# CC13x0 register map
File version: 2.0
CPU: CM3 r2p1, little endian, no MPU, no FPU, 0x3 interrupt priority bits, 0x0 interrupts
Registers are 32-bit, read-write, reset 0x0 unless marked. A register's access mark holds for its fields unless they carry their own. Offsets are from the block's base; [hi:lo] are bit positions; {n}, {i} and the like mark numbered series; 'fields as' and 'values as' point back to an identical list.

## AUX_SCE — AUX Sensor Control Engine Control Module
Base 0x400E1000
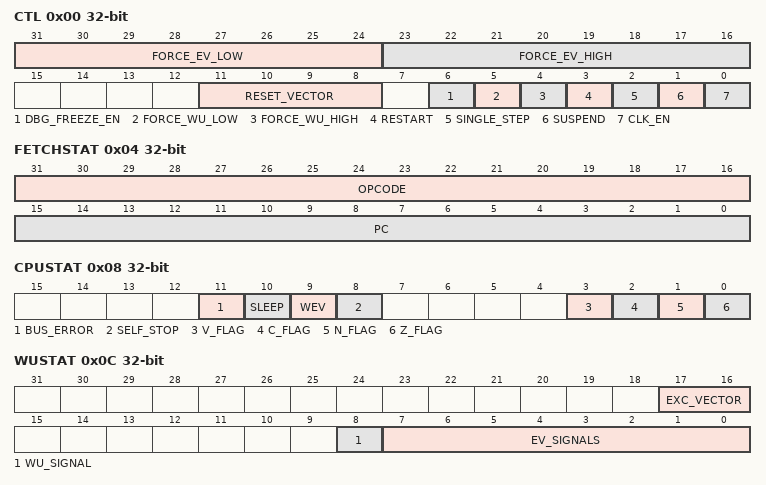
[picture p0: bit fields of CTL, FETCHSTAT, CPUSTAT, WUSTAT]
0x00 CTL — Internal. Only to be used through TI provided API.
  [31:24] FORCE_EV_LOW, [23:16] FORCE_EV_HIGH, [11:8] RESET_VECTOR, [6] DBG_FREEZE_EN, [5] FORCE_WU_LOW, [4] FORCE_WU_HIGH, [3] RESTART, [2] SINGLE_STEP, [1] SUSPEND, [0] CLK_EN
0x04 FETCHSTAT ro — Internal. Only to be used through TI provided API.
  [31:16] OPCODE, [15:0] PC
0x08 CPUSTAT ro — Internal. Only to be used through TI provided API.
  [11] BUS_ERROR, [10] SLEEP, [9] WEV, [8] SELF_STOP, [3] V_FLAG, [2] C_FLAG, [1] N_FLAG, [0] Z_FLAG
0x0C WUSTAT ro — Internal. Only to be used through TI provided API.
  [17:16] EXC_VECTOR, [8] WU_SIGNAL, [7:0] EV_SIGNALS
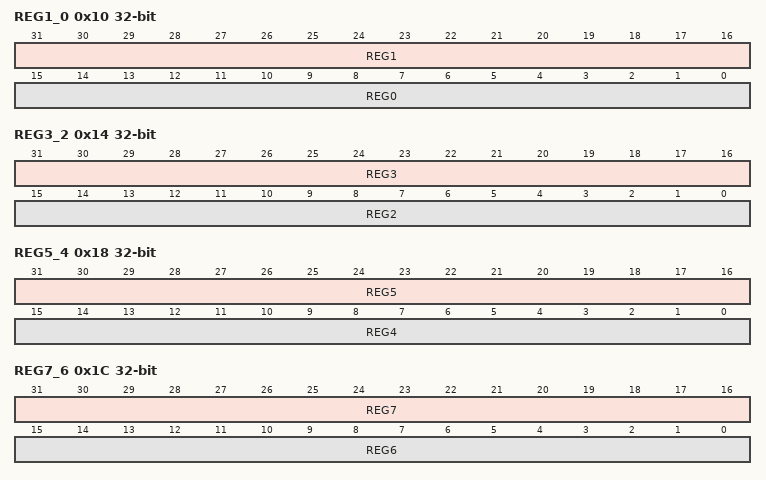
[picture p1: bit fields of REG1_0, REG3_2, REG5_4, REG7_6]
0x10 REG1_0 ro — Internal. Only to be used through TI provided API.
  [31:16] REG1, [15:0] REG0
0x14 REG3_2 ro — Internal. Only to be used through TI provided API.
  [31:16] REG3, [15:0] REG2
0x18 REG5_4 ro — Internal. Only to be used through TI provided API.
  [31:16] REG5, [15:0] REG4
0x1C REG7_6 ro — Internal. Only to be used through TI provided API.
  [31:16] REG7, [15:0] REG6
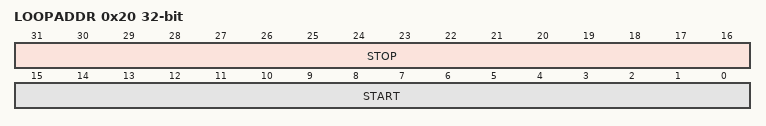
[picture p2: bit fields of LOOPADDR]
0x20 LOOPADDR ro — Internal. Only to be used through TI provided API.
  [31:16] STOP, [15:0] START
0x24 LOOPCNT ro — Internal. Only to be used through TI provided API.
  [7:0] ITER_LEFT

## AUX_SMPH — AUX Semaphore Controller
Base 0x400C8000
{0x0+4i} SMPH{i} reset 0x1 (i=0..7) — Semaphore {i}
  [0] STAT
0x20 AUTOTAKE — Sticky Request For Single Semaphore
  [2:0] SMPH_ID

## AUX_TDCIF — AUX Time To Digital Converter
Base 0x400C4000
0x00 CTL — Control
  [1:0] CMD
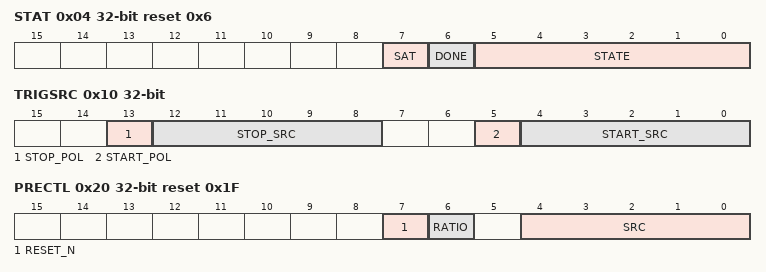
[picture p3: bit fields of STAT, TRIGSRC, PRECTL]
0x04 STAT ro reset 0x6 — Status
  [7] SAT, [6] DONE, [5:0] STATE
0x08 RESULT ro reset 0x2 — Result Result of last TDC conversion
  [24:0] VALUE
0x0C SATCFG reset 0xF — Saturation Configuration
  [3:0] LIMIT
0x10 TRIGSRC — Trigger Source TDC start/stop trigger source selection
  [13] STOP_POL, [12:8] STOP_SRC, [5] START_POL, [4:0] START_SRC
0x14 TRIGCNT — Trigger Counter Stop counter status/control of TDC
  [15:0] CNT
0x18 TRIGCNTLOAD — Trigger Counter Load Stop counter control of TDC
  [15:0] CNT
0x1C TRIGCNTCFG — Trigger Counter Configuration
  [0] EN
0x20 PRECTL reset 0x1F — Prescaler Control The prescaler can be used to count events that are faster than the AUX clock speed. It can be used standalone or as a start/stop source for the TDC by configuring TRIGSRC.START_SRC and TRIGSRC.STOP_SRC to TDC_PRE. When counting fast signals with the TDC that are faster than 1/10th of the clock frequency of AUX it is recommended to use the prescaler.
  [7] RESET_N, [6] RATIO, [4:0] SRC
0x24 PRECNT — Prescaler Counter Value of prescaler counter
  [15:0] CNT

## AUX_TIMER
Base 0x400C7000
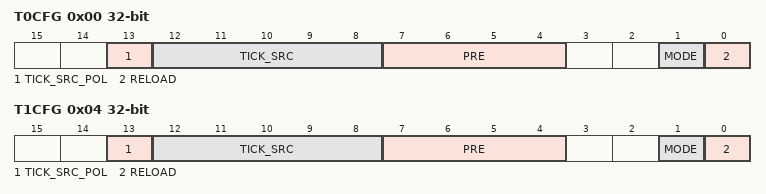
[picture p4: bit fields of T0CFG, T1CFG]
0x00 T0CFG — Timer 0 Configuration
  [13] TICK_SRC_POL, [12:8] TICK_SRC, [7:4] PRE, [1] MODE, [0] RELOAD
0x04 T1CFG — Timer 1 Configuration
  [13] TICK_SRC_POL, [12:8] TICK_SRC, [7:4] PRE, [1] MODE, [0] RELOAD
0x08 T0CTL — Timer 0 Control Run control/status for timer 0
  [0] EN
0x0C T0TARGET — Timer 0 Target Target counter value for timer 0
  [15:0] VALUE
0x10 T1TARGET — Timer 1 Target Target Counter Value Timer 1
  [7:0] VALUE
0x14 T1CTL — Timer 1 Control Run Control/Status For Timer 1
  [0] EN

## CPU_TIPROP — Cortex-M's TI proprietary registers
Base 0xE00FE000
0xFF8 TRACECLKMUX — Internal. Only to be used through TI provided API.
  [0] TRACECLK_N_SWV
0xFFC DYN_CG — Internal. Only to be used through TI provided API.
  [1:0] DYN_CG

## CRYPTO — Crypto core with DMA capability and local key storage
Base 0x40024000
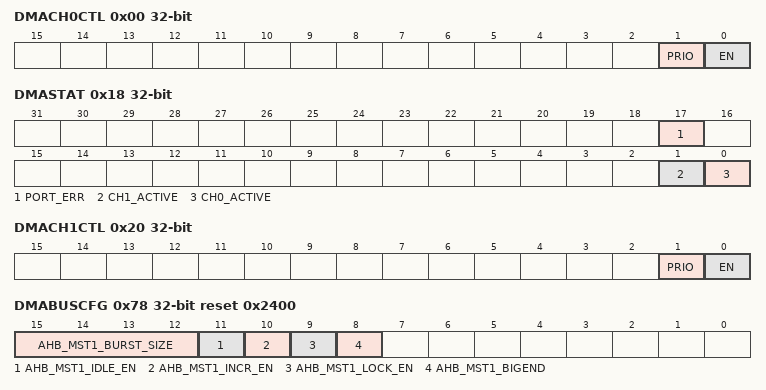
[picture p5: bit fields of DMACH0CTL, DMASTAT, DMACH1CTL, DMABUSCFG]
0x00 DMACH0CTL — DMA Channel 0 Control
  [1] PRIO, [0] EN
0x04 DMACH0EXTADDR — DMA Channel 0 External Address
  [31:0] ADDR
0x0C DMACH0LEN — DMA Channel 0 Length
  [15:0] LEN
0x18 DMASTAT ro — DMA Controller Status
  [17] PORT_ERR, [1] CH1_ACTIVE, [0] CH0_ACTIVE
0x1C DMASWRESET wo — DMA Controller Software Reset
  [0] RESET write-0-clears
0x20 DMACH1CTL — DMA Channel 1 Control
  [1] PRIO, [0] EN
0x24 DMACH1EXTADDR — DMA Channel 1 External Address
  [31:0] ADDR
0x2C DMACH1LEN — DMA Channel 1 Length
  [15:0] LEN
0x78 DMABUSCFG reset 0x2400 — DMA Controller Master Configuration
  [15:12] AHB_MST1_BURST_SIZE, [11] AHB_MST1_IDLE_EN, [10] AHB_MST1_INCR_EN, [9] AHB_MST1_LOCK_EN, [8] AHB_MST1_BIGEND
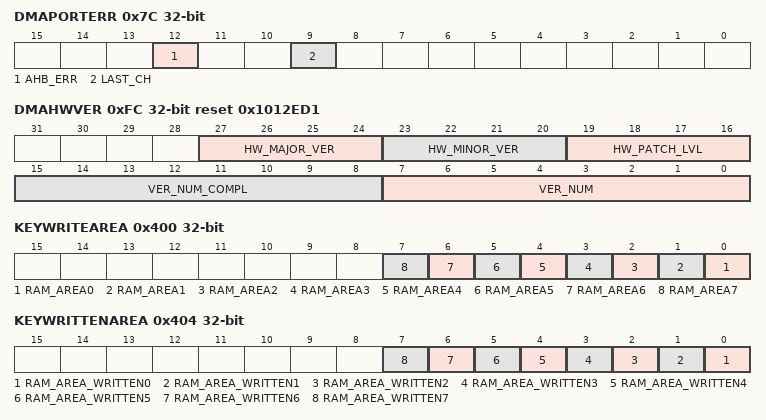
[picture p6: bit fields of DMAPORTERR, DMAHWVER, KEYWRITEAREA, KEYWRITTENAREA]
0x7C DMAPORTERR ro — DMA Controller Port Error
  [12] AHB_ERR, [9] LAST_CH
0xFC DMAHWVER ro reset 0x1012ED1 — DMA Controller Version
  [27:24] HW_MAJOR_VER, [23:20] HW_MINOR_VER, [19:16] HW_PATCH_LVL, [15:8] VER_NUM_COMPL, [7:0] VER_NUM
0x400 KEYWRITEAREA
  [n] RAM_AREA{n} (n=0..7)
0x404 KEYWRITTENAREA — Key Written Area Status This register shows which areas of the key store RAM contain valid written keys. When a new key needs to be written to the key store, on a location that is already occupied by a valid key, this key area must be cleared first. This can be done by writing this register before the new key is written to the key store memory. Attempting to write to a key area that already contains a valid key is not allowed and will result in an error.
  [n] RAM_AREA_WRITTEN{n} write-1-clears (n=0..7)
0x408 KEYSIZE reset 0x1 — Key Size This register defines the size of the keys that are written with DMA.
  [1:0] SIZE
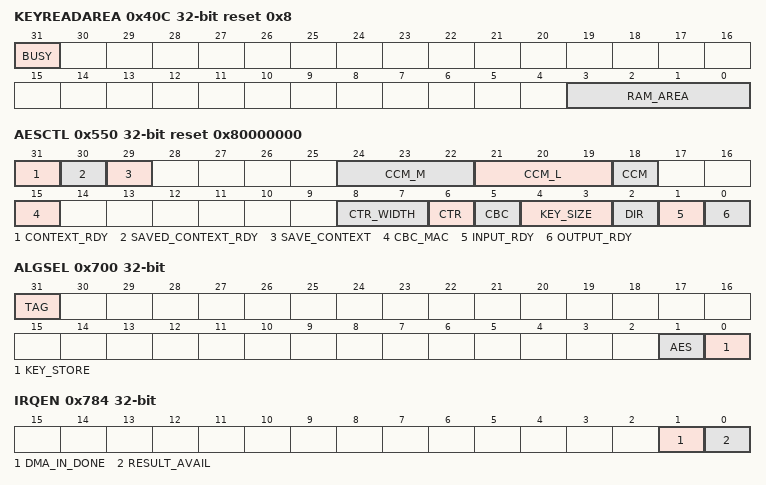
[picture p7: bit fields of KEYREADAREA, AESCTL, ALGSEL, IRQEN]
0x40C KEYREADAREA reset 0x8
  [31] BUSY, [3:0] RAM_AREA
{0x4B0+4i} AESKEY{i} wo (i=20..23) — Clear AES_KEY2/GHASH Key
  [31:0] KEY2
{0x498+4i} AESKEY{i} wo (i=30..33) — Clear AES_KEY3
  [31:0] KEY3
{0x540+4i} AESIV{i} (i=0..3) — AES Initialization Vector
  [31:0] IV
0x550 AESCTL reset 0x80000000 — AES Input/Output Buffer Control
  [31] CONTEXT_RDY, [30] SAVED_CONTEXT_RDY, [29] SAVE_CONTEXT, [24:22] CCM_M, [21:19] CCM_L, [18] CCM, [15] CBC_MAC, [8:7] CTR_WIDTH, [6] CTR, [5] CBC, [4:3] KEY_SIZE, [2] DIR, [1] INPUT_RDY, [0] OUTPUT_RDY
0x554 AESDATALEN0 wo — Crypto Data Length LSW
  [31:0] LEN_LSW
0x558 AESDATALEN1 wo — Crypto Data Length MSW
  [28:0] LEN_MSW
0x55C AESAUTHLEN wo — AES Authentication Length
  [31:0] LEN
0x560 AESDATAOUT0 ro — Data Input/Output
  [31:0] DATA
{0x560+4i} AESDATAIN{i} wo (i=0..2) — AES Data Input/Output {i}
  [31:0] DATA
0x564 AESDATAOUT1 ro — AES Data Input/Output 3
  [31:0] DATA
0x568 AESDATAOUT2 ro — AES Data Input/Output 2
  [31:0] DATA
0x56C AESDATAOUT3 ro — AES Data Input/Output 3
  [31:0] DATA
0x56C AESDATAIN3 wo — Data Input/Output
  [31:0] DATA
{0x570+4i} AESTAGOUT{i} ro (i=0..3) — AES Tag Output
  [31:0] TAG
0x700 ALGSEL — Master Algorithm Select This register configures the internal destination of the DMA controller.
  [31] TAG, [1] AES, [0] KEY_STORE
0x704 DMAPROTCTL — Master Protection Control
  [0] EN
0x740 SWRESET — Software Reset
  [0] RESET write-1-clears
0x780 IRQTYPE — Interrupt Configuration
  [0] IEN
0x784 IRQEN — Interrupt Enable
  [1] DMA_IN_DONE, [0] RESULT_AVAIL
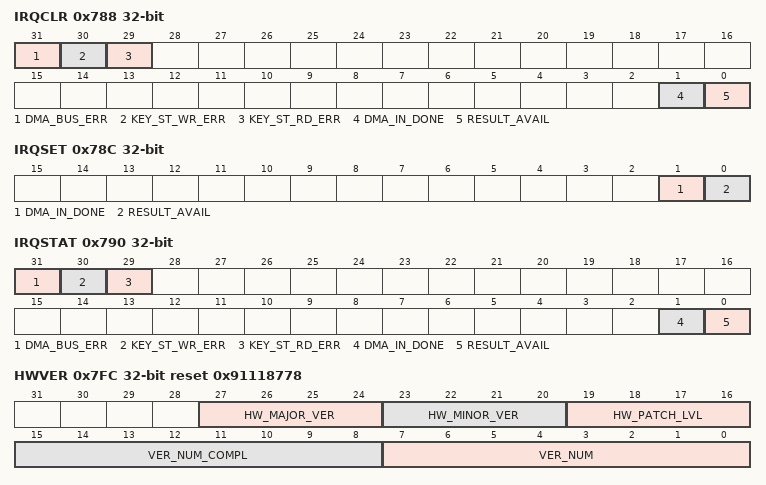
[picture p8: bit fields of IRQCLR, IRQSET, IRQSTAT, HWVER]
0x788 IRQCLR wo — Interrupt Clear
  [31] DMA_BUS_ERR, [30] KEY_ST_WR_ERR, [29] KEY_ST_RD_ERR, [1] DMA_IN_DONE, [0] RESULT_AVAIL
0x78C IRQSET wo — Interrupt Set
  [1] DMA_IN_DONE, [0] RESULT_AVAIL
0x790 IRQSTAT ro — Interrupt Status
  fields as IRQCLR
0x7FC HWVER ro reset 0x91118778 — CTRL Module Version
  fields as DMAHWVER
